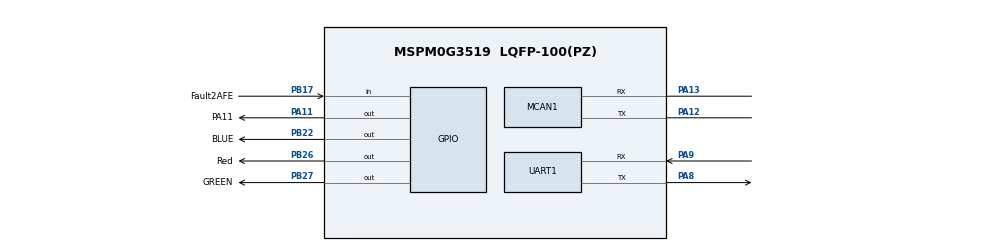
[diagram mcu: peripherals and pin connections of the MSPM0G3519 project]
//@cliArgs --device "MSPM0G351X" --package "LQFP-100(PZ)" --part "Default"
//@v2CliArgs --device "MSPM0G3519" --package "LQFP-100(PZ)"
// @cliArgs --board /ti/boards/LP_MSPM0G3519 --rtos nortos

/**
 * Import the modules used in this configuration.
 */
const GPIO    = scripting.addModule("/ti/driverlib/GPIO", {}, false);
const GPIO1   = GPIO.addInstance();
const GPIO2   = GPIO.addInstance();
const GPIO3   = GPIO.addInstance();
const GPIO4   = GPIO.addInstance();
const MCAN    = scripting.addModule("/ti/driverlib/MCAN", {}, false);
const MCAN1   = MCAN.addInstance();
const SYSCTL  = scripting.addModule("/ti/driverlib/SYSCTL");
const SYSTICK = scripting.addModule("/ti/driverlib/SYSTICK");
const TIMER   = scripting.addModule("/ti/driverlib/TIMER", {}, false);
const TIMER1  = TIMER.addInstance();
const UART    = scripting.addModule("/ti/driverlib/UART", {}, false);
const UART1   = UART.addInstance();

/**
 * Write custom configuration values to the imported modules.
 */
const divider7       = system.clockTree["PLL_PDIV"];
divider7.divideValue = 2;

const divider9       = system.clockTree["UDIV"];
divider9.divideValue = 2;

const multiplier2         = system.clockTree["PLL_QDIV"];
multiplier2.multiplyValue = 8;

const mux4       = system.clockTree["EXHFMUX"];
mux4.inputSelect = "EXHFMUX_XTAL";

const mux8       = system.clockTree["HSCLKMUX"];
mux8.inputSelect = "HSCLKMUX_SYSPLL0";

const mux12       = system.clockTree["SYSPLLMUX"];
mux12.inputSelect = "zSYSPLLMUX_HFCLK";

const pinFunction4       = system.clockTree["HFXT"];
pinFunction4.inputFreq   = 40;
pinFunction4.enable      = true;
pinFunction4.HFXTStartup = 100;

GPIO1.$name                          = "IOBQ78706";
GPIO1.associatedPins[0].$name        = "Fault2AFE";
GPIO1.associatedPins[0].direction    = "INPUT";
GPIO1.associatedPins[0].assignedPort = "PORTB";
GPIO1.associatedPins[0].assignedPin  = "17";
GPIO1.associatedPins[0].pin.$assign  = "PB17";

const Board = scripting.addModule("/ti/driverlib/Board", {}, false);

GPIO2.$name                          = "LED";
GPIO2.associatedPins.create(3);
GPIO2.associatedPins[0].$name        = "Red";
GPIO2.associatedPins[0].assignedPort = "PORTB";
GPIO2.associatedPins[0].assignedPin  = "26";
GPIO2.associatedPins[0].pin.$assign  = "PB26";
GPIO2.associatedPins[1].$name        = "GREEN";
GPIO2.associatedPins[1].assignedPort = "PORTB";
GPIO2.associatedPins[1].assignedPin  = "27";
GPIO2.associatedPins[1].pin.$assign  = "PB27";
GPIO2.associatedPins[2].$name        = "BLUE";
GPIO2.associatedPins[2].assignedPort = "PORTB";
GPIO2.associatedPins[2].assignedPin  = "22";
GPIO2.associatedPins[2].pin.$assign  = "PB22";

GPIO3.$name                          = "DBG";
GPIO3.associatedPins[0].$name        = "PA11";
GPIO3.associatedPins[0].assignedPort = "PORTA";
GPIO3.associatedPins[0].assignedPin  = "11";
GPIO3.associatedPins[0].pin.$assign  = "PA11";

GPIO4.$name                          = "BMU";
GPIO4.associatedPins.create(2);
GPIO4.associatedPins[0].$name        = "WAKEIN";
GPIO4.associatedPins[0].assignedPort = "PORTB";
GPIO4.associatedPins[0].assignedPin  = "5";
GPIO4.associatedPins[0].initialValue = "SET";
GPIO4.associatedPins[1].$name        = "WAKEOUT";
GPIO4.associatedPins[1].assignedPort = "PORTB";
GPIO4.associatedPins[1].assignedPin  = "21";

MCAN1.$name                    = "MCAN0";
MCAN1.fdMode                   = false;
MCAN1.wkupReqEnable            = true;
MCAN1.autoWkupEnable           = true;
MCAN1.emulationEnable          = true;
MCAN1.tdcEnable                = true;
MCAN1.spPercent                = 80;
MCAN1.lss                      = 10;
MCAN1.stdFiltElem              = "001";
MCAN1.stdFiltType              = "10";
MCAN1.flesa                    = 40;
MCAN1.lse                      = 10;
MCAN1.extFiltElem              = "001";
MCAN1.extFiltType              = "10";
MCAN1.extFiltID2               = 536870911;
MCAN1.txStartAddr              = 120;
MCAN1.txBufNum                 = 10;
MCAN1.txBufElemSize            = "DL_MCAN_ELEM_SIZE_8BYTES";
MCAN1.txEventFIFOStartAddr     = 280;
MCAN1.txEventFIFOSize          = 4;
MCAN1.txEventFIFOWaterMark     = 1;
MCAN1.rxFIFO0startAddr         = 312;
MCAN1.rxFIFO0size              = 10;
MCAN1.rxBufElemSize            = "DL_MCAN_ELEM_SIZE_8BYTES";
MCAN1.rxFIFO0ElemSize          = "DL_MCAN_ELEM_SIZE_8BYTES";
MCAN1.rxFIFO1ElemSize          = "DL_MCAN_ELEM_SIZE_8BYTES";
MCAN1.rxFIFO0waterMark         = 0;
MCAN1.rxFIFO1startAddr         = 472;
MCAN1.rxFIFO1size              = 4;
MCAN1.rxFIFO1OpMode            = "1";
MCAN1.rxBufStartAddr           = 536;
MCAN1.additionalCoreConfig     = true;
MCAN1.rrfe                     = true;
MCAN1.rrfs                     = true;
MCAN1.anfe                     = "1";
MCAN1.anfs                     = "1";
MCAN1.overrideRetention        = true;
MCAN1.enableInterrupt          = true;
MCAN1.interruptFlags           = ["DL_MCAN_INTERRUPT_ARA","DL_MCAN_INTERRUPT_BEU","DL_MCAN_INTERRUPT_BO","DL_MCAN_INTERRUPT_ELO","DL_MCAN_INTERRUPT_EP","DL_MCAN_INTERRUPT_EW","DL_MCAN_INTERRUPT_MRAF","DL_MCAN_INTERRUPT_PEA","DL_MCAN_INTERRUPT_PED","DL_MCAN_INTERRUPT_TOO","DL_MCAN_INTERRUPT_TSW","DL_MCAN_INTERRUPT_WDI"];
MCAN1.interruptLine            = ["DL_MCAN_INTR_LINE_NUM_1"];
MCAN1.interruptLine1Flag       = ["DL_MCAN_INTR_MASK_ALL"];
MCAN1.m0interrupts             = ["DL_MCAN_MSP_INTERRUPT_LINE1"];
MCAN1.stdFiltID1               = 255;
MCAN1.stdFiltID2               = 2047;
MCAN1.peripheral.$assign       = "CANFD0";
MCAN1.peripheral.rxPin.$assign = "PA13";
MCAN1.peripheral.txPin.$assign = "PA12";
scripting.suppress("SysConfig currently does not support configuration of more than one filter\\. More filters can be added in the user application, however care must be taken to ensure that enough RAM is allocated during initialization\\.", MCAN1, "lss");
scripting.suppress("SysConfig currently does not support configuration of more than one filter\\. More filters can be added in the user application, however care must be taken to ensure that enough RAM is allocated during initialization\\.", MCAN1, "lse");

SYSCTL.forceDefaultClkConfig = true;
SYSCTL.clockTreeEn           = true;
scripting.suppress("For best practices when the CPUCLK is running at 32MHz and above, clear the flash status bit using DL_FlashCTL_executeClearStatus\\(\\) before executing any flash operation\\. Otherwise there may be false positives\\.", SYSCTL);

SYSTICK.periodEnable      = true;
SYSTICK.period            = 800000;
SYSTICK.interruptEnable   = true;
SYSTICK.interruptPriority = "3";
SYSTICK.systickEnable     = true;

TIMER1.$name              = "TIMER_BQTASK";
TIMER1.timerClkDiv        = 4;
TIMER1.timerClkPrescale   = 200;
TIMER1.timerPeriod        = "1 s";
TIMER1.interrupts         = ["ZERO"];
TIMER1.peripheral.$assign = "TIMG0";

UART1.$name                    = "UART_0";
UART1.targetBaudRate           = 1000000;
UART1.enableFIFO               = true;
UART1.rxFifoThreshold          = "DL_UART_RX_FIFO_LEVEL_ONE_ENTRY";
UART1.txFifoThreshold          = "DL_UART_TX_FIFO_LEVEL_EMPTY";
UART1.enabledInterrupts        = ["RX"];
UART1.peripheral.$assign       = "UART1";
UART1.peripheral.rxPin.$assign = "PA9";
UART1.peripheral.txPin.$assign = "PA8";
